# CEC1736_S0_2HW device description
Architecture: CORTEX-M4; Family: CEC173X; Series: CEC
Registers are 32-bit, read-write, reset 0x0 unless marked. A register's access mark holds for its fields unless they carry their own. Offsets are from the block's base; [hi:lo] are bit positions; {n}, {i} and the like mark numbered series.

## DMA_CHAN00 — DMA Channel 00 Registers
Instances: DMA_CHAN00 0x40002440
0x00 ACTIVATE 8-bit — Enable this channel for operation. The DMA Main Control: Activate must also be enabled for this channel to be operational.
  [0] CHN — Enable this channel for operation. The DMA Main Control:Activate must also be enabled for this channel to be operational. 1=Enable channel(block). Each individual channel must be enabled separately. 0=Disable channel(block).
0x04 MSTART — This is the starting address for the Memory device.
0x08 MEND — This is the ending address for the Memory device.
0x0C DSTART — This is the Master Device address.
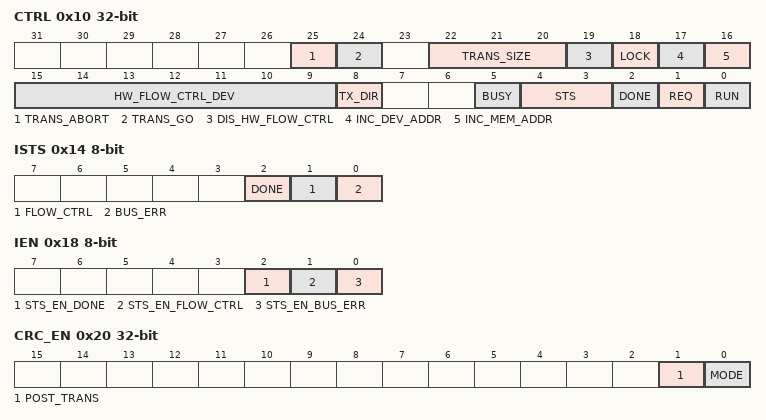
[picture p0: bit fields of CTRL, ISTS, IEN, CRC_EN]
0x10 CTRL — DMA Channel N Control
  [25] TRANS_ABORT — This is used to abort the current transfer on this DMA Channel. The aborted transfer will be forced to terminate immediately.
  [24] TRANS_GO — This is used for the Firmware Flow Control DMA transfer.
  [22:20] TRANS_SIZE — This is the transfer size in Bytes of each Data Packet transfer. Note: The transfer size must be a legal AMBA transfer size. Valid sizes are 1, 2 and 4 Bytes.
  [19] DIS_HW_FLOW_CTRL — This will Disable the Hardware Flow Control. When disabled, any DMA Master device attempting to communicate to the DMA over the DMA Flow Control Interface (Ports: dma_req, dma_term, and dma_done) will be ignored. This should be set before using the DMA channel in Firmware Flow Control mode.
  [18] LOCK — This is used to lock the arbitration of the Channel Arbiter on this channel once this channel is granted. Once this is locked, it will remain on the arbiter until it has completed it transfer (either the Transfer Aborted, Transfer Done or Transfer Terminated conditions).
  [17] INC_DEV_ADDR — This will enable an auto-increment to the DMA Channel Device Address. 1: Increment the DMA Channel Device Address by DMA Channel Control:Transfer Size after every Data Packet transfer 0: Do nothing
  [16] INC_MEM_ADDR — This will enable an auto-increment to the DMA Channel Memory Address. 1=Increment the DMA Channel Memory Address by DMA Channel Control:Transfer Size after every Data Packet transfer 0=Do nothing
  [15:9] HW_FLOW_CTRL_DEV — This is the device that is connected to this channel as its Hardware Flow Control master. The Flow Control Interface is a bus with each master concatenated onto it. This selects which bus index of the concatenated Flow Control Interface bus is targeted towards this channel. The Flow Control Interface Port list is dma_req, dma_term, and dma_done.
  [8] TX_DIR — This determines the direction of the DMA Transfer. 1=Data Packet Read from Memory Start Address followed by Data Packet Write to Device Address 0=Data Packet Read from Device Address followed by Data Packet Write to Memory Start Address
  [5] BUSY — This is a status signal. 1=The DMA Channel is busy (FSM is not IDLE) 0=The DMA Channel is not busy (FSM is IDLE)
  [4:3] STS — This is a status signal. The status decode is listed in priority order with the highest priority first. 3: Error detected by the DMA 2: The DMA Channel is externally done, in that the Device has terminated the transfer over the Hardware Flow Control through the Port dma_term 1: The DMA Channel is locally done, in that Memory Start Address equals Memory End Address 0: DMA Channel Control:Run is Disabled (0x0)
    3=ERROR (3: Error detected by the DMA); 2=EXT_DONE (2: The DMA Channel is externally done, in that the Device has terminated the transfer over the Hardware Flow Control through the Port dma_term); 1=LOC_DONE (1: The DMA Channel is locally done, in that Memory Start Address equals Memory End Address); 0=DIS (0: DMA Channel Control:Run is Disabled (0x0))
  [2] DONE — This is a status signal. It is only valid while DMA Channel Control: Run is Enabled. This is the inverse of the DMA Channel Control: Busy field, except this is qualified with the DMA Channel Control:Run field. 1=Channel is done 0=Channel is not done or it is OFF
  [1] REQ — This is a status field. 1= There is a transfer request from the Master Device 0= There is no transfer request from the Master Device
  [0] RUN — This is a control field. Note: This bit only applies to Hardware Flow Control mode. 1= This channel is enabled and will service transfer requests 0=This channel is disabled. All transfer requests are ignored.
0x14 ISTS 8-bit — DMA Channel N Interrupt Status
  [2] DONE — This is an interrupt source register. This flags when the DMA Channel has completed a transfer successfully on its side. A completed transfer is defined as when the DMA Channel reaches its limit; Memory Start Address equals Memory End Address. A completion due to a Hardware Flow Control Terminate will not flag this interrupt. 1=Memory Start Address equals Memory End Address 0=Memory Start Address does not equal Memory End Address
  [1] FLOW_CTRL — This is an interrupt source register. This flags when the DMA Channel has encountered a Hardware Flow Control Request after the DMA Channel has completed the transfer. This means the Master Device is attempting to overflow the DMA. 1=Hardware Flow Control is requesting after the transfer has completed 0=No Hardware Flow Control event
  [0] BUS_ERR — This is an interrupt source register. This flags when there is an Error detected over the internal 32-bit Bus. 1: Error detected. (R/WC)
0x18 IEN 8-bit — DMA CHANNEL N INTERRUPT ENABLE
  [2] STS_EN_DONE — This is an interrupt enable for DMA Channel Interrupt:Status Done. 1=Enable Interrupt 0=Disable Interrupt
  [1] STS_EN_FLOW_CTRL — This is an interrupt enable for DMA Channel Interrupt:Status Flow Control Error. 1=Enable Interrupt 0=Disable Interrupt
  [0] STS_EN_BUS_ERR — This is an interrupt enable for DMA Channel Interrupt:Status Bus Error. 1=Enable Interrupt 0=Disable Interrupt
0x20 CRC_EN — DMA CHANNEL N CRC ENABLE
  [1] POST_TRANS — The bit enables the transfer of the calculated CRC-32 after the completion of the DMA transaction. If the DMA transaction is aborted by either firmware or an internal bus error, the transfer will not occur. If the target of the DMA transfer is a device and the device signaled the termination of the DMA transaction, the CRC post transfer will not occur. 1=Enable the transfer of CRC-32 for DMA Channel N after the DMA transaction completes 0=Disable the automatic transfer of the CRC
  [0] MODE — 1=Enable the calculation of CRC-32 for DMA Channel N 0=Disable the calculation of CRC-32 for DMA Channel N
0x24 CRC_DATA — DMA CHANNEL N CRC DATA
  [31:0] CRC — Writes to this register initialize the CRC generator. Reads from this register return the output of the CRC that is calculated from the data transferred by DMA Channel N. The output of the CRC generator is bit-reversed and inverted on reads, as required by the CRC-32-IEEE definition. A CRC can be accumulated across multiple DMA transactions on Channel N. If it is necessary to save the intermediate CRC value, the result of the read of this register must be bit-reversed and inverted before being written back to this register.
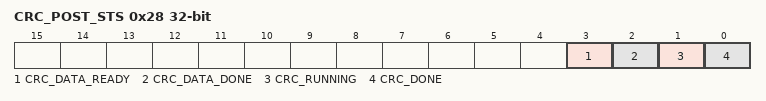
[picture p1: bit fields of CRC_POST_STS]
0x28 CRC_POST_STS — DMA CHANNEL N CRC POST STATUS
  [3] CRC_DATA_READY — This bit is set to '1b' when the DMA controller is processing the post-transfer of the CRC data. This bit is cleared to '0b' when the post-transfer completes.
  [2] CRC_DATA_DONE — This bit is set to '1b' when the DMA controller has completed the post-transfer of the CRC data. This bit is cleared to '0b' when the a new DMA transfer starts.
  [1] CRC_RUNNING — This bit is set to '1b' when the DMA controller starts the post-transfer transmission of the CRC. It is only set when the post-transfer is enabled by the CRC_POST_TRANSFER_ENABLE field. This bit is cleared to '0b' when the post-transfer completes.
  [0] CRC_DONE — This bit is set to '1b' when the CRC calculation has completed from either normal or forced termination. It is cleared to '0b' when the DMA controller starts a new transfer on the channel.
Value list DMA_CHAN00_CTRL__TRANS_SIZE: 1=BYTE (1 byte transfer); 2=HWORD (2 byte transfer); 4=WORD (4 byte transfer)
Value list DMA_CHAN00_CTRL__TX_DIR: 0=DEV_TO_MEM (Read from device, write to memory); 1=MEM_TO_DEV (Read from memory, write to device)

## DMA_CHAN01 — DMA Channel 01 Registers
Instances: DMA_CHAN01 0x40002480
Registers as DMA_CHAN00, without CRC_EN, CRC_DATA, CRC_POST_STS; these are added or differ:
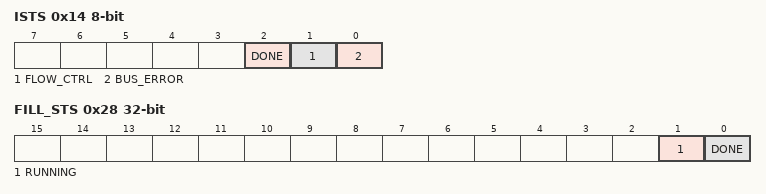
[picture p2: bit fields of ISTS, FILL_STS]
0x14 ISTS 8-bit — DMA Channel N Interrupt Status
  [2] DONE — This is an interrupt source register. This flags when the DMA Channel has completed a transfer successfully on its side. A completed transfer is defined as when the DMA Channel reaches its limit; Memory Start Address equals Memory End Address. A completion due to a Hardware Flow Control Terminate will not flag this interrupt. 1=Memory Start Address equals Memory End Address 0=Memory Start Address does not equal Memory End Address
  [1] FLOW_CTRL — This is an interrupt source register. This flags when the DMA Channel has encountered a Hardware Flow Control Request after the DMA Channel has completed the transfer. This means the Master Device is attempting to overflow the DMA. 1=Hardware Flow Control is requesting after the transfer has completed 0=No Hardware Flow Control event
  [0] BUS_ERROR — This is an interrupt source register. This flags when there is an Error detected over the internal 32-bit Bus. 1: Error detected. (R/WC)
0x20 FILL_EN — DMA CHANNEL N FILL ENABLE
  [0] MODE — 1=Enable the DMA Channel Fill Engine N 0=Disable the DMA Channel Fill Engine
0x24 FILL_DATA — DMA CHANNEL N FILL DATA
  [31:0] DATA — This is the data pattern used to fill memory.
0x28 FILL_STS — DMA CHANNEL N FILL STATUS
  [1] RUNNING — This bit is set to '1b' when the DMA controller starts the post-transfer transmission of the CRC. It is only set when the post-transfer is enabled by the CRC_POST_TRANSFER_ENABLE field. This bit is cleared to '0b' when the post-transfer completes.
  [0] DONE — This bit is set to '1b' when the CRC calculation has completed from either normal or forced termination. It is cleared to '0b' when the DMA controller starts a new transfer on the channel.
Value list DMA_CHAN01_CTRL__TRANS_SIZE: 1=BYTE (1 byte transfer); 2=HWORD (2 byte transfer); 4=WORD (4 byte transfer)
Value list DMA_CHAN00_CTRL__TX_DIR: 0=DEV_TO_MEM (Read from device, write to memory); 1=MEM_TO_DEV (Read from memory, write to device)

## DMA_CHAN02 — DMA Channel 02 Registers
Instances: DMA_CHAN{n:02} {0x40002440+0x40*n} (n=2..9)
Registers as DMA_CHAN00, without CRC_EN, CRC_DATA, CRC_POST_STS.
Value list DMA_CHAN02_CTRL__TRANS_SIZE: 1=BYTE (1 byte transfer); 2=HWORD (2 byte transfer); 4=WORD (4 byte transfer)
Value list DMA_CHAN00_CTRL__TX_DIR: 0=DEV_TO_MEM (Read from device, write to memory); 1=MEM_TO_DEV (Read from memory, write to device)
